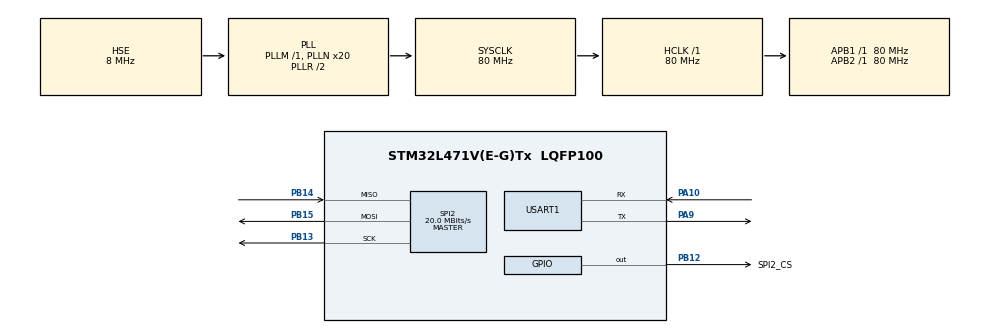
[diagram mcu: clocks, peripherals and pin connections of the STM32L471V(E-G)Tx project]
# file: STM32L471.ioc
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Dma.Request0=USART1_RX
Dma.USART1_RX.0.Direction=DMA_PERIPH_TO_MEMORY
Dma.USART1_RX.0.Instance=DMA1_Channel5
Dma.USART1_RX.0.MemDataAlignment=DMA_MDATAALIGN_BYTE
Dma.USART1_RX.0.MemInc=DMA_MINC_ENABLE
Dma.USART1_RX.0.Mode=DMA_CIRCULAR
Dma.USART1_RX.0.PeriphDataAlignment=DMA_PDATAALIGN_BYTE
Dma.USART1_RX.0.PeriphInc=DMA_PINC_DISABLE
Dma.USART1_RX.0.Priority=DMA_PRIORITY_LOW
Mcu.Family=STM32L4
Mcu.Name=STM32L471V(E-G)Tx
Mcu.Package=LQFP100
NVIC.DMA1_Channel5_IRQn=true\:0\:0\:false\:false\:true\:false\:true\:true
NVIC.PriorityGroup=NVIC_PRIORITYGROUP_4
NVIC.USART1_IRQn=true\:0\:0\:false\:false\:true\:true\:true\:true
PA10.Mode=Asynchronous
PA10.Signal=USART1_RX
PA13\ (JTMS-SWDIO).Mode=Serial_Wire
PA13\ (JTMS-SWDIO).Signal=SYS_JTMS-SWDIO
PA14\ (JTCK-SWCLK).Mode=Serial_Wire
PA14\ (JTCK-SWCLK).Signal=SYS_JTCK-SWCLK
PA9.Mode=Asynchronous
PA9.Signal=USART1_TX
PB12.GPIO_Label=SPI2_CS
PB12.GPIO_Speed=GPIO_SPEED_FREQ_HIGH
PB12.PinState=GPIO_PIN_SET
PB12.Signal=GPIO_Output
PB13.Mode=Full_Duplex_Master
PB13.Signal=SPI2_SCK
PB14.Mode=Full_Duplex_Master
PB14.Signal=SPI2_MISO
PB15.Mode=Full_Duplex_Master
PB15.Signal=SPI2_MOSI
PC10.Signal=USART3_TX
PC11.Signal=USART3_RX
PC14-OSC32_IN\ (PC14).Mode=LSE-External-Oscillator
PC14-OSC32_IN\ (PC14).Signal=RCC_OSC32_IN
PC15-OSC32_OUT\ (PC15).Mode=LSE-External-Oscillator
PC15-OSC32_OUT\ (PC15).Signal=RCC_OSC32_OUT
PD5.Signal=USART2_TX
PD6.Signal=USART2_RX
PH0-OSC_IN\ (PH0).Mode=HSE-External-Oscillator
PH0-OSC_IN\ (PH0).Signal=RCC_OSC_IN
PH1-OSC_OUT\ (PH1).Mode=HSE-External-Oscillator
PH1-OSC_OUT\ (PH1).Signal=RCC_OSC_OUT
ProjectManager.HeapSize=0x800
ProjectManager.StackSize=0x800
ProjectManager.TargetToolchain=MDK-ARM V5.32
RCC.ADCFreq_Value=64000000
RCC.AHBFreq_Value=80000000
RCC.APB1Freq_Value=80000000
RCC.APB1TimFreq_Value=80000000
RCC.APB2Freq_Value=80000000
RCC.APB2TimFreq_Value=80000000
RCC.CortexFreq_Value=80000000
RCC.HCLKFreq_Value=80000000
RCC.HSE_VALUE=8000000
RCC.HSI_VALUE=16000000
RCC.MSI_VALUE=4000000
RCC.PLLN=20
RCC.PLLSAI1N=16
RCC.PLLSourceVirtual=RCC_PLLSOURCE_HSE
RCC.SYSCLKFreq_VALUE=80000000
RCC.SYSCLKSource=RCC_SYSCLKSOURCE_PLLCLK
RCC.VCOOutputFreq_Value=160000000
SPI2.BaudRatePrescaler=SPI_BAUDRATEPRESCALER_4
SPI2.CalculateBaudRate=20.0 MBits/s
SPI2.DataSize=SPI_DATASIZE_8BIT
SPI2.Direction=SPI_DIRECTION_2LINES
SPI2.Mode=SPI_MODE_MASTER
SPI2.VirtualType=VM_MASTER
USART1.VirtualMode-Asynchronous=VM_ASYNC
board=custom

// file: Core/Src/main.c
/* USER CODE BEGIN Header */
/**
  ******************************************************************************
  * @file           : main.c
  * @brief          : Main program body
  ******************************************************************************
  * @attention
  *
  * Copyright (c) 2026 STMicroelectronics.
  * All rights reserved.
  *
  * This software is licensed under terms that can be found in the LICENSE file
  * in the root directory of this software component.
  * If no LICENSE file comes with this software, it is provided AS-IS.
  *
  ******************************************************************************
  */
/* USER CODE END Header */
#include "main.h"
#include "dma.h"
#include "spi.h"
#include "usart.h"
#include "gpio.h"

/* USER CODE BEGIN Includes */
#include "log.h"
#include "rtos_app.h"
/* USER CODE END Includes */

void SystemClock_Config(void);

int main(void)
{

  /* MCU Configuration--------------------------------------------------------*/

  /* Reset of all peripherals, Initializes the Flash interface and the Systick. */
  HAL_Init();

  /* Configure the system clock */
  SystemClock_Config();

  /* Initialize all configured peripherals */
  MX_GPIO_Init();
  MX_DMA_Init();
  MX_USART1_UART_Init();
  MX_SPI2_Init();
  /* USER CODE BEGIN 2 */
log_init(&huart1); // 假设 log 用的是 huart1，根据实际修改
    log_printf("\r\n================================\r\n");
    log_printf("   LittleFS YModem File Transfer\r\n");
    log_printf("================================\r\n");
    app_init();
  /* USER CODE END 2 */

  /* Infinite loop */
  while (1)
  {

    /* USER CODE BEGIN 3 */
    app_poll();
  }
  /* USER CODE END 3 */
}

void SystemClock_Config(void)
{
  RCC_OscInitTypeDef RCC_OscInitStruct = {0};
  RCC_ClkInitTypeDef RCC_ClkInitStruct = {0};

  /** Configure the main internal regulator output voltage
  */
  if (HAL_PWREx_ControlVoltageScaling(PWR_REGULATOR_VOLTAGE_SCALE1) != HAL_OK)
  {
    Error_Handler();
  }

  /** Initializes the RCC Oscillators according to the specified parameters
  * in the RCC_OscInitTypeDef structure.
  */
  RCC_OscInitStruct.OscillatorType = RCC_OSCILLATORTYPE_HSE;
  RCC_OscInitStruct.HSEState = RCC_HSE_ON;
  RCC_OscInitStruct.PLL.PLLState = RCC_PLL_ON;
  RCC_OscInitStruct.PLL.PLLSource = RCC_PLLSOURCE_HSE;
  RCC_OscInitStruct.PLL.PLLM = 1;
  RCC_OscInitStruct.PLL.PLLN = 20;
  RCC_OscInitStruct.PLL.PLLP = RCC_PLLP_DIV7;
  RCC_OscInitStruct.PLL.PLLQ = RCC_PLLQ_DIV2;
  RCC_OscInitStruct.PLL.PLLR = RCC_PLLR_DIV2;
  if (HAL_RCC_OscConfig(&RCC_OscInitStruct) != HAL_OK)
  {
    Error_Handler();
  }

  /** Initializes the CPU, AHB and APB buses clocks
  */
  RCC_ClkInitStruct.ClockType = RCC_CLOCKTYPE_HCLK|RCC_CLOCKTYPE_SYSCLK
                              |RCC_CLOCKTYPE_PCLK1|RCC_CLOCKTYPE_PCLK2;
  RCC_ClkInitStruct.SYSCLKSource = RCC_SYSCLKSOURCE_PLLCLK;
  RCC_ClkInitStruct.AHBCLKDivider = RCC_SYSCLK_DIV1;
  RCC_ClkInitStruct.APB1CLKDivider = RCC_HCLK_DIV1;
  RCC_ClkInitStruct.APB2CLKDivider = RCC_HCLK_DIV1;

  if (HAL_RCC_ClockConfig(&RCC_ClkInitStruct, FLASH_LATENCY_4) != HAL_OK)
  {
    Error_Handler();
  }
}

void Error_Handler(void)
{
  __disable_irq();
  while (1)
  {
  }
}
